CM_ "IMPORT _community.dbc";
CM_ "IMPORT _honda_common.dbc";
CM_ "IMPORT _nidec_common.dbc";
CM_ "IMPORT _lkas_hud_5byte.dbc";
CM_ "IMPORT _nidec_scm_group_a.dbc";
CM_ "IMPORT _steering_sensors_b.dbc";
CM_ "IMPORT _steering_control_b.dbc";

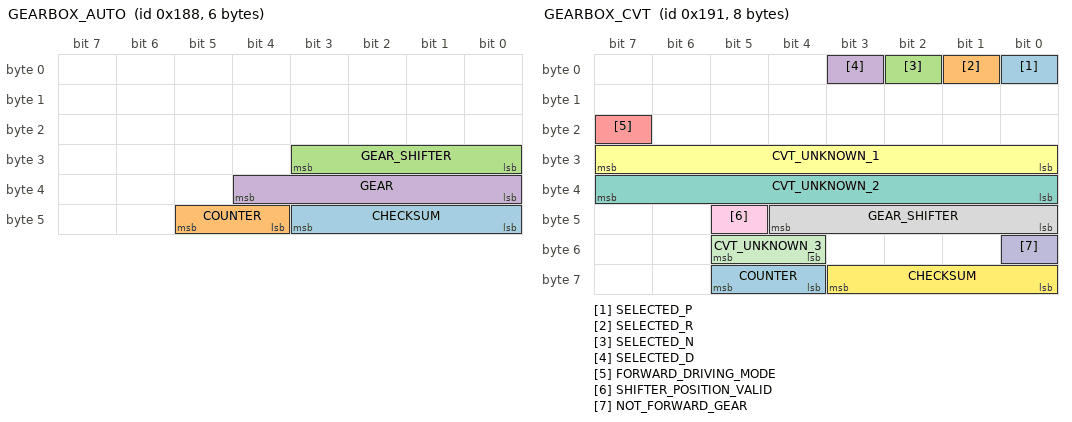
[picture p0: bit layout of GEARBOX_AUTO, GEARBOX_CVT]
BO_ 392 GEARBOX_AUTO: 6 XXX
 SG_ CHECKSUM : 43|4@0+ (1,0) [0|15] "" XXX
 SG_ COUNTER : 45|2@0+ (1,0) [0|3] "" XXX
 SG_ GEAR_SHIFTER : 27|4@0+ (1,0) [0|15] "" EON
 SG_ GEAR : 36|5@0+ (1,0) [0|31] "" EON

CM_ "Gearbox CVT only added for interface querying, not used by car"

BO_ 401 GEARBOX_CVT: 8 PCM
 SG_ SELECTED_P : 0|1@0+ (1,0) [0|1] "" XXX
 SG_ SELECTED_R : 1|1@0+ (1,0) [0|1] "" XXX
 SG_ SELECTED_N : 2|1@0+ (1,0) [0|1] "" XXX
 SG_ SELECTED_D : 3|1@0+ (1,0) [0|1] "" XXX
 SG_ FORWARD_DRIVING_MODE : 23|1@0+ (1,0) [0|1] "" XXX
 SG_ CVT_UNKNOWN_1 : 31|8@0+ (1,0) [0|255] "" XXX
 SG_ CVT_UNKNOWN_2 : 39|8@0+ (1,0) [0|255] "" XXX
 SG_ GEAR_SHIFTER : 44|5@0+ (1,0) [0|31] "" XXX
 SG_ SHIFTER_POSITION_VALID : 45|1@0+ (1,0) [0|1] "" XXX
 SG_ NOT_FORWARD_GEAR : 48|1@0+ (1,0) [0|1] "" XXX
 SG_ CVT_UNKNOWN_3 : 53|2@0+ (1,0) [0|3] "" XXX
 SG_ CHECKSUM : 59|4@0+ (1,0) [0|15] "" EON
 SG_ COUNTER : 61|2@0+ (1,0) [0|3] "" EON

VAL_ 392 GEAR_SHIFTER 0 "S" 1 "P" 2 "R" 4 "N" 8 "D" ;
VAL_ 392 GEAR 26 "S" 4 "D" 3 "N" 2 "R" 1 "P" ;
VAL_ 401 GEAR_SHIFTER 1 "P" 2 "R" 3 "N" 4 "D" 7 "L" 10 "S";

CM_ SG_ 401 CVT_UNKNOWN_1 "Probably measured/actual CVT ratio";
CM_ SG_ 401 CVT_UNKNOWN_2 "Probably target/commanded CVT ratio";
